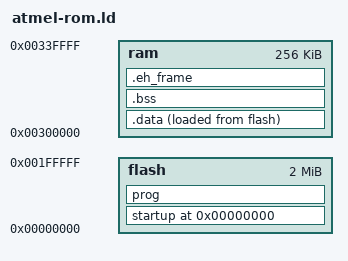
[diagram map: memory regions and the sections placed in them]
MEMORY 
{
	flash	: ORIGIN = 0x00000000, LENGTH = 2048K
	ram		: ORIGIN = 0x00300000, LENGTH = 256K
}

__stack_end__ = 0x00300000 + 256K - 4;

SECTIONS 
{
	. = 0;
	startup : { *(.startup)} >flash

	prog : 
	{
		*(.text)
		*(.rodata)
		*(.rodata*)
		*(.glue_7)
		*(.glue_7t)
	} >flash

	__end_of_text__ = .;

	.data : 
	{
		__data_beg__ = .;
		__data_beg_src__ = __end_of_text__;
		*(.data)
		__data_end__ = .;
	} >ram AT>flash

	.bss : 
	{
		__bss_beg__ = .;
		*(.bss)
	} >ram

	. = ALIGN(4);
	.eh_frame :
	{
		 KEEP (*(.eh_frame))
	} > ram
	
	/* Align here to ensure that the .bss section occupies space up to
	_end.  Align after .bss to ensure correct alignment even if the
	.bss section disappears because there are no input sections.  */
	. = ALIGN(32 / 8);
}
	. = ALIGN(32 / 8);
	_end = .;
	_bss_end__ = . ; __bss_end__ = . ; __end__ = . ;
	PROVIDE (end = .);


